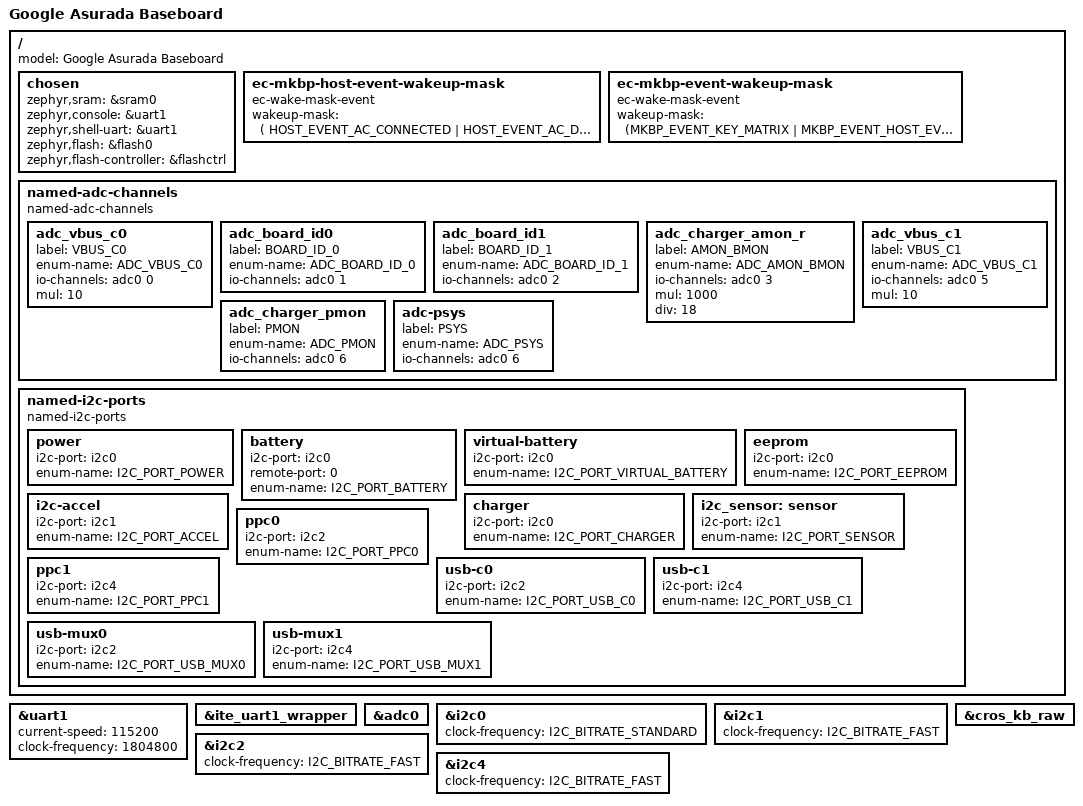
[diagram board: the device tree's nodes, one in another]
/* Copyright 2021 The Chromium OS Authors. All rights reserved.
 * Use of this source code is governed by a BSD-style license that can be
 * found in the LICENSE file.
 */

/dts-v1/;

#include <cros/ite/it8xxx2.dtsi>
#include <dt-bindings/adc/adc.h>
#include <dt-bindings/gpio_defines.h>
#include <it8xxx2.dtsi>
#include <dt-bindings/wake_mask_event_defines.h>

/ {
	model = "Google Asurada Baseboard";

	chosen {
		zephyr,sram = &sram0;
		zephyr,console = &uart1;
		zephyr,shell-uart = &uart1;
		zephyr,flash = &flash0;
		zephyr,flash-controller = &flashctrl;
	};

	ec-mkbp-host-event-wakeup-mask {
		compatible = "ec-wake-mask-event";
		wakeup-mask = <(
			HOST_EVENT_AC_CONNECTED |
			HOST_EVENT_AC_DISCONNECTED |
			HOST_EVENT_LID_OPEN |
			HOST_EVENT_POWER_BUTTON |
			HOST_EVENT_HANG_DETECT |
			HOST_EVENT_MODE_CHANGE)>;
	};

	ec-mkbp-event-wakeup-mask {
		compatible = "ec-wake-mask-event";
		wakeup-mask = <(MKBP_EVENT_KEY_MATRIX |
				MKBP_EVENT_HOST_EVENT)>;
	};

	named-adc-channels {
		compatible = "named-adc-channels";

		adc_vbus_c0 {
			label = "VBUS_C0";
			enum-name = "ADC_VBUS_C0";
			io-channels = <&adc0 0>;
			mul = <10>;
		};
		adc_board_id0 {
			label = "BOARD_ID_0";
			enum-name = "ADC_BOARD_ID_0";
			io-channels = <&adc0 1>;
		};
		adc_board_id1 {
			label = "BOARD_ID_1";
			enum-name = "ADC_BOARD_ID_1";
			io-channels = <&adc0 2>;
		};
		adc_charger_amon_r {
			label = "AMON_BMON";
			enum-name = "ADC_AMON_BMON";
			io-channels = <&adc0 3>;
			mul = <1000>;
			div = <18>;
		};
		adc_vbus_c1 {
			label = "VBUS_C1";
			enum-name = "ADC_VBUS_C1";
			io-channels = <&adc0 5>;
			mul = <10>;
		};
		adc_charger_pmon {
			label = "PMON";
			enum-name = "ADC_PMON";
			io-channels = <&adc0 6>;
		};
		adc-psys {
			label = "PSYS";
			enum-name = "ADC_PSYS";
			io-channels = <&adc0 6>;
		};
	};

	named-i2c-ports {
		compatible = "named-i2c-ports";

		power {
			i2c-port = <&i2c0>;
			enum-name = "I2C_PORT_POWER";
		};
		battery {
			i2c-port = <&i2c0>;
			remote-port = <0>;
			enum-name = "I2C_PORT_BATTERY";
		};
		virtual-battery {
			i2c-port = <&i2c0>;
			enum-name = "I2C_PORT_VIRTUAL_BATTERY";
		};
		eeprom {
			i2c-port = <&i2c0>;
			enum-name = "I2C_PORT_EEPROM";
		};
		charger {
			i2c-port = <&i2c0>;
			enum-name = "I2C_PORT_CHARGER";
		};
		i2c_sensor: sensor {
			i2c-port = <&i2c1>;
			enum-name = "I2C_PORT_SENSOR";
		};
		i2c-accel {
			i2c-port = <&i2c1>;
			enum-name = "I2C_PORT_ACCEL";
		};
		ppc0 {
			i2c-port = <&i2c2>;
			enum-name = "I2C_PORT_PPC0";
		};
		ppc1 {
			i2c-port = <&i2c4>;
			enum-name = "I2C_PORT_PPC1";
		};
		usb-c0 {
			i2c-port = <&i2c2>;
			enum-name = "I2C_PORT_USB_C0";
		};
		usb-c1 {
			i2c-port = <&i2c4>;
			enum-name = "I2C_PORT_USB_C1";
		};
		usb-mux0 {
			i2c-port = <&i2c2>;
			enum-name = "I2C_PORT_USB_MUX0";
		};
		usb-mux1 {
			i2c-port = <&i2c4>;
			enum-name = "I2C_PORT_USB_MUX1";
		};
	};
};

&uart1 {
	status = "okay";
	current-speed = <115200>;
	clock-frequency = <1804800>;
};

&ite_uart1_wrapper {
	status = "okay";
};

&adc0 {
	status = "okay";
};

&i2c0 {
	/* EC_I2C_PWR_CBI */
	status = "okay";
	clock-frequency = <I2C_BITRATE_STANDARD>;
};

&i2c1 {
	/* EC_I2C_SENSOR */
	status = "okay";
	clock-frequency = <I2C_BITRATE_FAST>;
};

&i2c2 {
	/* EC_I2C_USB_C0 */
	status = "okay";
	clock-frequency = <I2C_BITRATE_FAST>;
};

&i2c4{
	/* EC_I2C_USB_C1 */
	status = "okay";
	clock-frequency = <I2C_BITRATE_FAST>;
};

&cros_kb_raw {
	status = "okay";
};
